# iom480ae register map
Registers are 32-bit, access not given, no defined reset value unless marked. A register's access mark holds for its fields unless they carry their own. Addresses are absolute; registers are grouped by the start of their names; [hi:lo] are bit positions.

## UART1
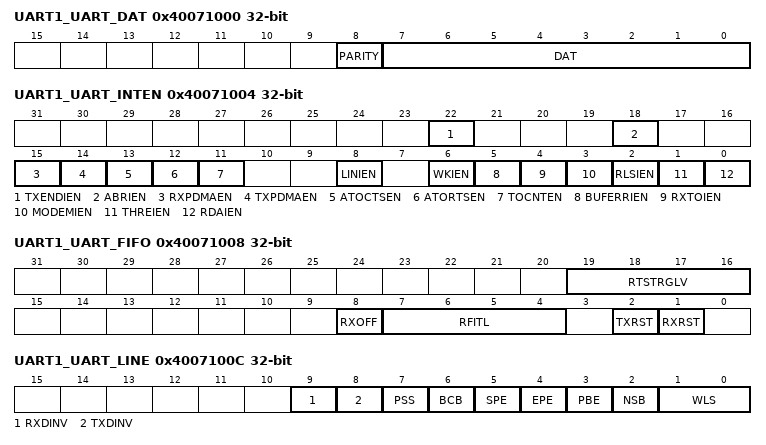
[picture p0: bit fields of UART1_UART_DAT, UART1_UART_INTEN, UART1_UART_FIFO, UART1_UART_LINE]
0x40071000 UART1_UART_DAT
  [8] PARITY, [7:0] DAT
0x40071004 UART1_UART_INTEN
  [22] TXENDIEN, [18] ABRIEN, [15] RXPDMAEN, [14] TXPDMAEN, [13] ATOCTSEN, [12] ATORTSEN, [11] TOCNTEN, [8] LINIEN, [6] WKIEN, [5] BUFERRIEN, [4] RXTOIEN, [3] MODEMIEN, [2] RLSIEN, [1] THREIEN, [0] RDAIEN
0x40071008 UART1_UART_FIFO
  [19:16] RTSTRGLV, [8] RXOFF, [7:4] RFITL, [2] TXRST, [1] RXRST
0x4007100C UART1_UART_LINE
  [9] RXDINV, [8] TXDINV, [7] PSS, [6] BCB, [5] SPE, [4] EPE, [3] PBE, [2] NSB, [1:0] WLS
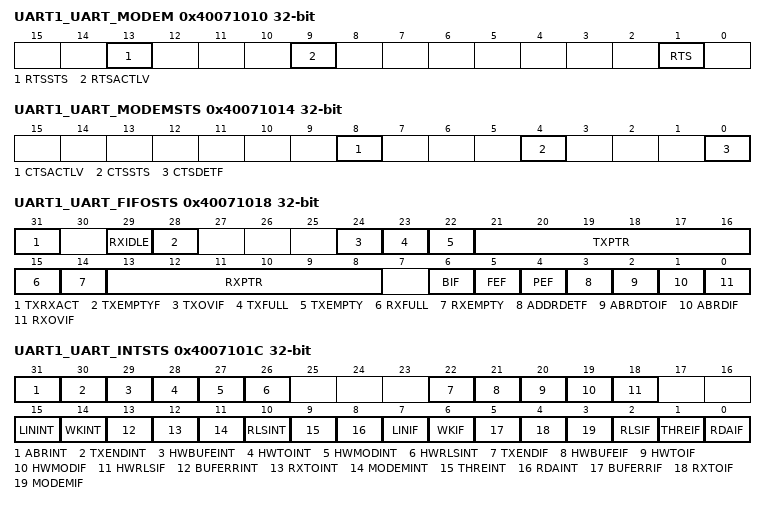
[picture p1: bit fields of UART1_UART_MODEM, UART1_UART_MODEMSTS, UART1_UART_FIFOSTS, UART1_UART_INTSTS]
0x40071010 UART1_UART_MODEM
  [13] RTSSTS, [9] RTSACTLV, [1] RTS
0x40071014 UART1_UART_MODEMSTS
  [8] CTSACTLV, [4] CTSSTS, [0] CTSDETF
0x40071018 UART1_UART_FIFOSTS
  [31] TXRXACT, [29] RXIDLE, [28] TXEMPTYF, [24] TXOVIF, [23] TXFULL, [22] TXEMPTY, [21:16] TXPTR, [15] RXFULL, [14] RXEMPTY, [13:8] RXPTR, [6] BIF, [5] FEF, [4] PEF, [3] ADDRDETF, [2] ABRDTOIF, [1] ABRDIF, [0] RXOVIF
0x4007101C UART1_UART_INTSTS
  [31] ABRINT, [30] TXENDINT, [29] HWBUFEINT, [28] HWTOINT, [27] HWMODINT, [26] HWRLSINT, [22] TXENDIF, [21] HWBUFEIF, [20] HWTOIF, [19] HWMODIF, [18] HWRLSIF, [15] LININT, [14] WKINT, [13] BUFERRINT, [12] RXTOINT, [11] MODEMINT, [10] RLSINT, [9] THREINT, [8] RDAINT, [7] LINIF, [6] WKIF, [5] BUFERRIF, [4] RXTOIF, [3] MODEMIF, [2] RLSIF, [1] THREIF, [0] RDAIF
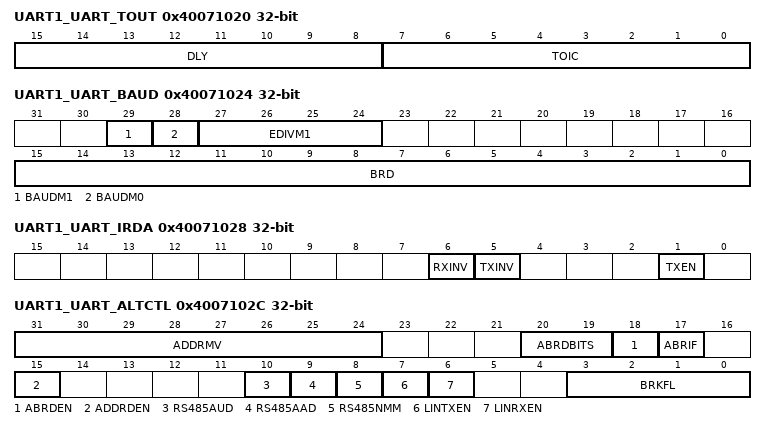
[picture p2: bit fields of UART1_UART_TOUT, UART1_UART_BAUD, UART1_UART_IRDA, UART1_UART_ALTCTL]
0x40071020 UART1_UART_TOUT
  [15:8] DLY, [7:0] TOIC
0x40071024 UART1_UART_BAUD
  [29] BAUDM1, [28] BAUDM0, [27:24] EDIVM1, [15:0] BRD
0x40071028 UART1_UART_IRDA
  [6] RXINV, [5] TXINV, [1] TXEN
0x4007102C UART1_UART_ALTCTL
  [31:24] ADDRMV, [20:19] ABRDBITS, [18] ABRDEN, [17] ABRIF, [15] ADDRDEN, [10] RS485AUD, [9] RS485AAD, [8] RS485NMM, [7] LINTXEN, [6] LINRXEN, [3:0] BRKFL
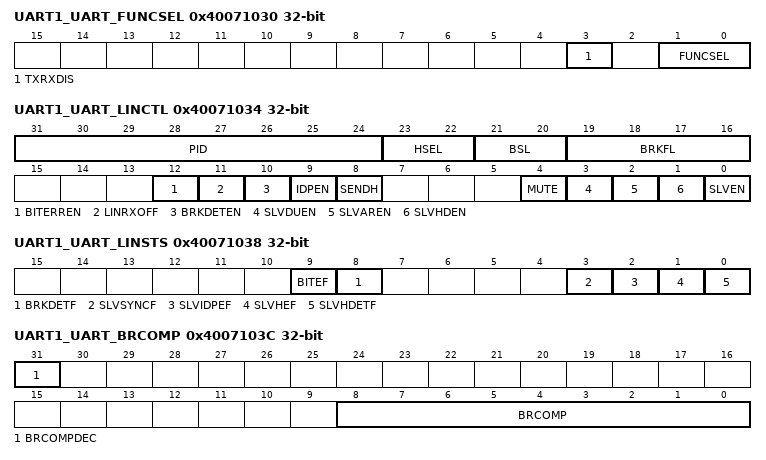
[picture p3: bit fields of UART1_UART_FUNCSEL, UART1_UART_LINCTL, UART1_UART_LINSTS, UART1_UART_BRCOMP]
0x40071030 UART1_UART_FUNCSEL
  [3] TXRXDIS, [1:0] FUNCSEL
0x40071034 UART1_UART_LINCTL
  [31:24] PID, [23:22] HSEL, [21:20] BSL, [19:16] BRKFL, [12] BITERREN, [11] LINRXOFF, [10] BRKDETEN, [9] IDPEN, [8] SENDH, [4] MUTE, [3] SLVDUEN, [2] SLVAREN, [1] SLVHDEN, [0] SLVEN
0x40071038 UART1_UART_LINSTS
  [9] BITEF, [8] BRKDETF, [3] SLVSYNCF, [2] SLVIDPEF, [1] SLVHEF, [0] SLVHDETF
0x4007103C UART1_UART_BRCOMP
  [31] BRCOMPDEC, [8:0] BRCOMP
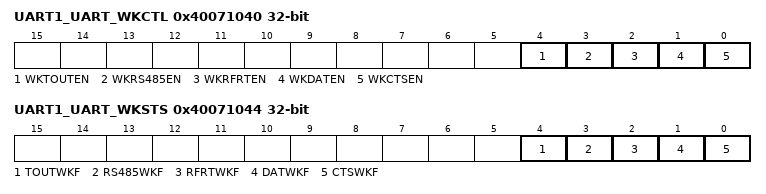
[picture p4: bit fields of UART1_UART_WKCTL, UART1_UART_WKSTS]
0x40071040 UART1_UART_WKCTL
  [4] WKTOUTEN, [3] WKRS485EN, [2] WKRFRTEN, [1] WKDATEN, [0] WKCTSEN
0x40071044 UART1_UART_WKSTS
  [4] TOUTWKF, [3] RS485WKF, [2] RFRTWKF, [1] DATWKF, [0] CTSWKF
0x40071048 UART1_UART_DWKCOMP
  [15:0] STCOMP

## UART2
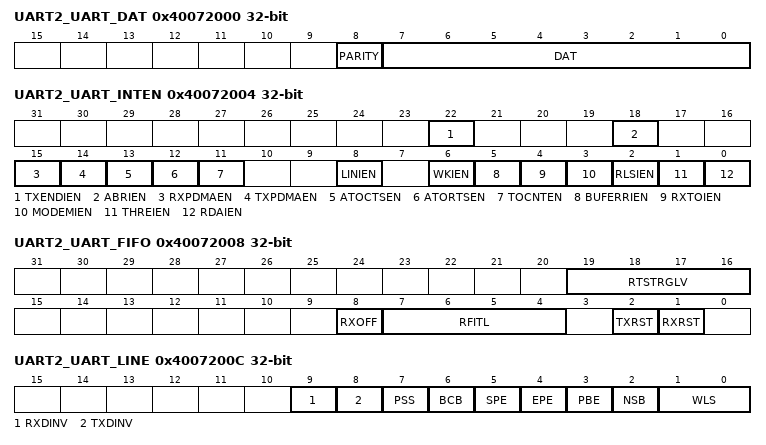
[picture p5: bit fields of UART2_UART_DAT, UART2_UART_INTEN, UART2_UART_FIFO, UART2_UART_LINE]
0x40072000 UART2_UART_DAT
  [8] PARITY, [7:0] DAT
0x40072004 UART2_UART_INTEN
  [22] TXENDIEN, [18] ABRIEN, [15] RXPDMAEN, [14] TXPDMAEN, [13] ATOCTSEN, [12] ATORTSEN, [11] TOCNTEN, [8] LINIEN, [6] WKIEN, [5] BUFERRIEN, [4] RXTOIEN, [3] MODEMIEN, [2] RLSIEN, [1] THREIEN, [0] RDAIEN
0x40072008 UART2_UART_FIFO
  [19:16] RTSTRGLV, [8] RXOFF, [7:4] RFITL, [2] TXRST, [1] RXRST
0x4007200C UART2_UART_LINE
  [9] RXDINV, [8] TXDINV, [7] PSS, [6] BCB, [5] SPE, [4] EPE, [3] PBE, [2] NSB, [1:0] WLS
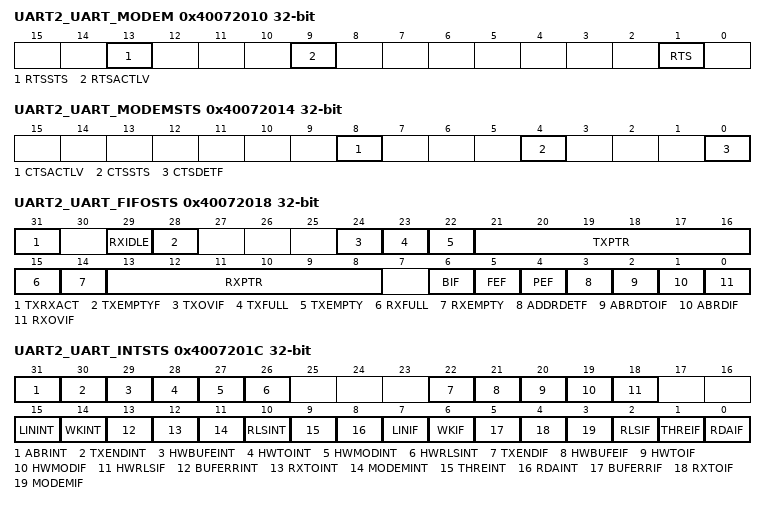
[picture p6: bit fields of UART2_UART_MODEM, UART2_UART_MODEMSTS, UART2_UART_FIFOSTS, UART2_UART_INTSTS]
0x40072010 UART2_UART_MODEM
  [13] RTSSTS, [9] RTSACTLV, [1] RTS
0x40072014 UART2_UART_MODEMSTS
  [8] CTSACTLV, [4] CTSSTS, [0] CTSDETF
0x40072018 UART2_UART_FIFOSTS
  [31] TXRXACT, [29] RXIDLE, [28] TXEMPTYF, [24] TXOVIF, [23] TXFULL, [22] TXEMPTY, [21:16] TXPTR, [15] RXFULL, [14] RXEMPTY, [13:8] RXPTR, [6] BIF, [5] FEF, [4] PEF, [3] ADDRDETF, [2] ABRDTOIF, [1] ABRDIF, [0] RXOVIF
0x4007201C UART2_UART_INTSTS
  [31] ABRINT, [30] TXENDINT, [29] HWBUFEINT, [28] HWTOINT, [27] HWMODINT, [26] HWRLSINT, [22] TXENDIF, [21] HWBUFEIF, [20] HWTOIF, [19] HWMODIF, [18] HWRLSIF, [15] LININT, [14] WKINT, [13] BUFERRINT, [12] RXTOINT, [11] MODEMINT, [10] RLSINT, [9] THREINT, [8] RDAINT, [7] LINIF, [6] WKIF, [5] BUFERRIF, [4] RXTOIF, [3] MODEMIF, [2] RLSIF, [1] THREIF, [0] RDAIF
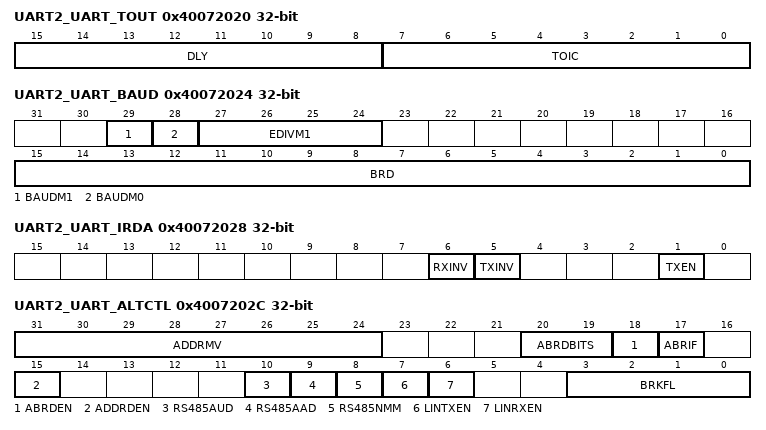
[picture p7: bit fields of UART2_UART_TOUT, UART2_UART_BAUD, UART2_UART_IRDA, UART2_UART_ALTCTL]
0x40072020 UART2_UART_TOUT
  [15:8] DLY, [7:0] TOIC
0x40072024 UART2_UART_BAUD
  [29] BAUDM1, [28] BAUDM0, [27:24] EDIVM1, [15:0] BRD
0x40072028 UART2_UART_IRDA
  [6] RXINV, [5] TXINV, [1] TXEN
0x4007202C UART2_UART_ALTCTL
  [31:24] ADDRMV, [20:19] ABRDBITS, [18] ABRDEN, [17] ABRIF, [15] ADDRDEN, [10] RS485AUD, [9] RS485AAD, [8] RS485NMM, [7] LINTXEN, [6] LINRXEN, [3:0] BRKFL
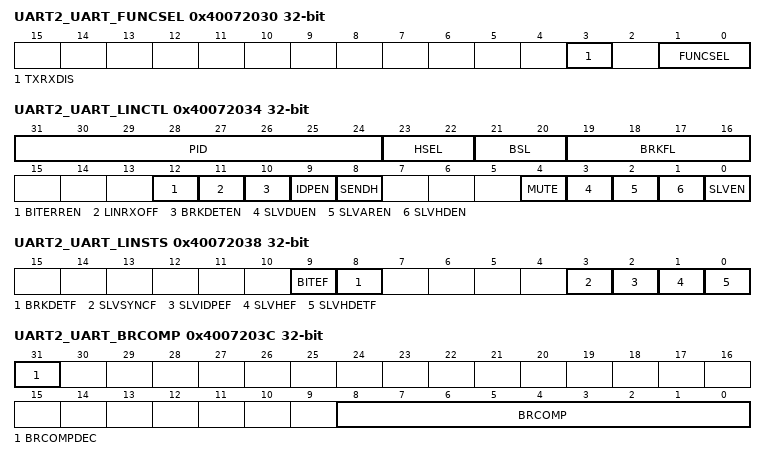
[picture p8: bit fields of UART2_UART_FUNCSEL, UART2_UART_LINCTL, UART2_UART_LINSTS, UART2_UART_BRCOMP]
0x40072030 UART2_UART_FUNCSEL
  [3] TXRXDIS, [1:0] FUNCSEL
0x40072034 UART2_UART_LINCTL
  [31:24] PID, [23:22] HSEL, [21:20] BSL, [19:16] BRKFL, [12] BITERREN, [11] LINRXOFF, [10] BRKDETEN, [9] IDPEN, [8] SENDH, [4] MUTE, [3] SLVDUEN, [2] SLVAREN, [1] SLVHDEN, [0] SLVEN
0x40072038 UART2_UART_LINSTS
  [9] BITEF, [8] BRKDETF, [3] SLVSYNCF, [2] SLVIDPEF, [1] SLVHEF, [0] SLVHDETF
0x4007203C UART2_UART_BRCOMP
  [31] BRCOMPDEC, [8:0] BRCOMP
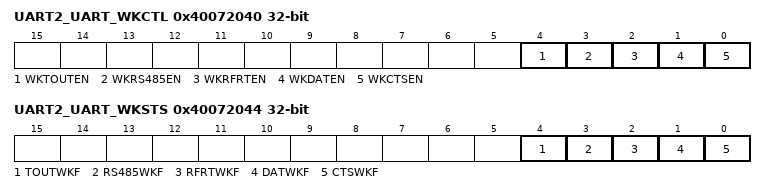
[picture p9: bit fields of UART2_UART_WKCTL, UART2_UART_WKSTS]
0x40072040 UART2_UART_WKCTL
  [4] WKTOUTEN, [3] WKRS485EN, [2] WKRFRTEN, [1] WKDATEN, [0] WKCTSEN
0x40072044 UART2_UART_WKSTS
  [4] TOUTWKF, [3] RS485WKF, [2] RFRTWKF, [1] DATWKF, [0] CTSWKF
0x40072048 UART2_UART_DWKCOMP
  [15:0] STCOMP
